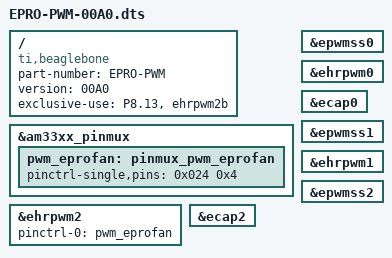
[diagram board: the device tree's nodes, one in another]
/*
 *	DTS to enable PWM on pin P8_13, EPRO FAN
 *
 */
/dts-v1/;
/plugin/;

/ {
   	compatible = "ti,beaglebone", "ti,beaglebone-black";

        /* identification */
        part-number = "EPRO-PWM";
        version = "00A0";

         /* state the resources this cape uses */
        exclusive-use = "P8.13","ehrpwm2b";


        fragment@0 {
                target = <&am33xx_pinmux>;
                __overlay__ {
                        pwm_eprofan: pinmux_pwm_eprofan {
                                pinctrl-single,pins = <0x024  0x4>; /* P8_13 | MODE 4 */
                        };
                };
        };

	fragment@1 {
		target = <&epwmss0>;
		__overlay__ {
			status = "okay";
		};
	};

	fragment@2 {
		target = <&ehrpwm0>;
		__overlay__ {
			status = "okay";
		};
	};

	fragment@3 {
		target = <&ecap0>;
		__overlay__ {
			status = "okay";
		};
	};

	fragment@4 {
		target = <&epwmss1>;
		__overlay__ {
			status = "okay";
		};
	};

	fragment@5 {
		target = <&ehrpwm1>;
		__overlay__ {
			status = "okay";
		};
	};


	fragment@6 {
		target = <&epwmss2>;
		__overlay__ {
			status = "okay";
		};
	};

	fragment@7 {
		target = <&ehrpwm2>;
		__overlay__ {
			pinctrl-names   = "default";
			pinctrl-0	= <&pwm_eprofan>;
			status = "okay";
		};
	};

	fragment@8 {
		target = <&ecap2>;
		__overlay__ {
			status = "okay";
		};
	};

};

